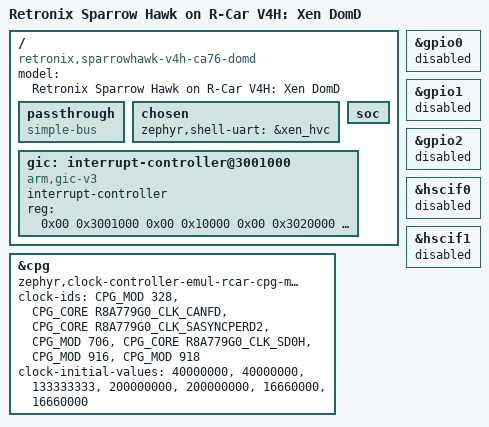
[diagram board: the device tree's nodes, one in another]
/*
 * Copyright (C) 2025 TOKITA Hiroshi
 *
 * SPDX-License-Identifier: Apache-2.0
 */

#include <mem.h>
#include <zephyr/dt-bindings/gpio/gpio.h>
#include <zephyr/dt-bindings/clock/r8a779g0_cpg_mssr.h>

/delete-node/ &gic;

/ {
	compatible = "retronix,sparrowhawk-v4h-ca76-domd";
	model = "Retronix Sparrow Hawk on R-Car V4H: Xen DomD";

	passthrough {
		compatible = "simple-bus";
		ranges;
		#address-cells = <2>;
		#size-cells = <2>;
	};

	chosen {
		zephyr,shell-uart = &xen_hvc;
	};

	soc {
		#address-cells = <2>;
		#size-cells = <2>;
	};

	gic: interrupt-controller@3001000 {
		compatible = "arm,gic-v3", "arm,gic";
		#interrupt-cells = <4>;
		#address-cells = <0>;
		interrupt-controller;
		reg = <0x00 0x3001000 0x00 0x10000 0x00 0x3020000 0x00 0x1000000>;
	};
};

&cpg {
	compatible = "zephyr,clock-controller-emul-rcar-cpg-mssr";
	#clock-cells = <2>;
	clock-ids = <CPG_MOD 328>,
		    <CPG_CORE R8A779G0_CLK_CANFD>,
		    <CPG_CORE R8A779G0_CLK_SASYNCPERD2>,
		    <CPG_MOD 706>,
		    <CPG_CORE R8A779G0_CLK_SD0H>,
		    <CPG_MOD 916>,
		    <CPG_MOD 918>;
	clock-initial-values = <40000000>, <40000000>, <133333333>, <200000000>,
			       <200000000>, <16660000>, <16660000>;
};

&gpio0 {
	status = "disabled";
};

&gpio1 {
	status = "disabled";
};

&gpio2 {
	status = "disabled";
};

&hscif0 {
	status = "disabled";
};

&hscif1 {
	status = "disabled";
};
